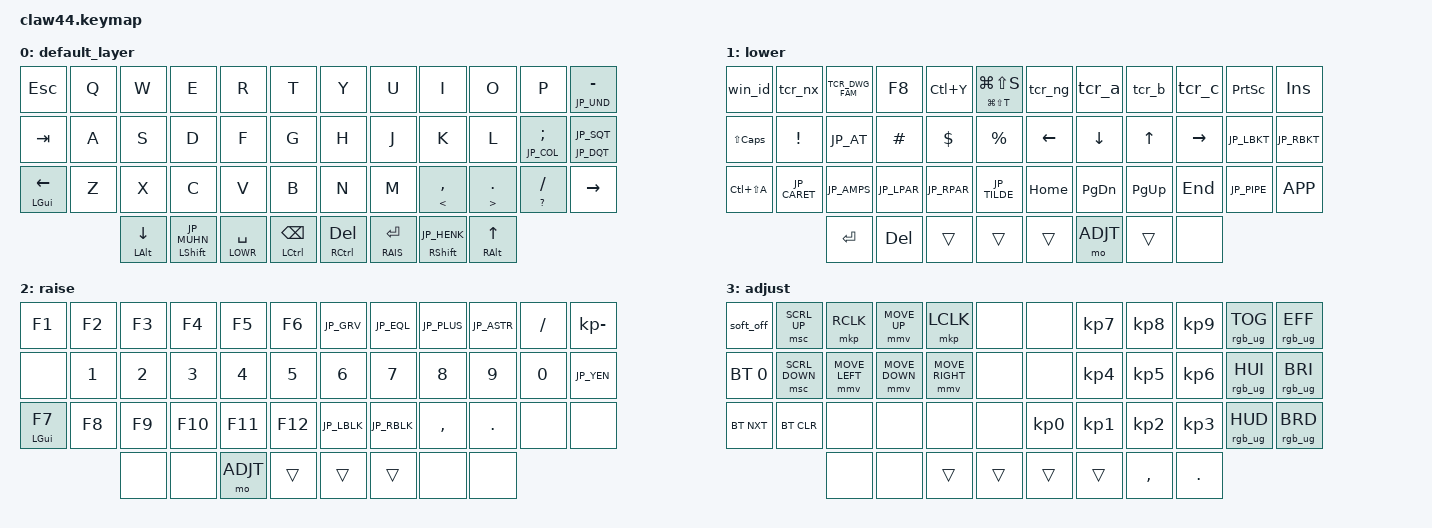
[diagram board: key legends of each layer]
/*
 * Copyright (c) 2021 The ZMK Contributors
 *
 * SPDX-License-Identifier: MIT
 */

#include <behaviors.dtsi>
#include <dt-bindings/zmk/keys.h>
#include <dt-bindings/zmk/bt.h>
#include <dt-bindings/zmk/outputs.h>
#include <dt-bindings/zmk/pointing.h>
#include <dt-bindings/zmk/rgb.h>

#define LOWR 1
#define RAIS 2
#define ADJT 3

/* the following lines are for using Claw44 on JIS layout */
#define JP_UND   LS(INT1)  // _
#define JP_COL   SQT       // :
#define JP_SQT   LS(N7)    // '
#define JP_DQT   LS(N2)    // "
#define JP_MUHN  INT5      // mukenkan
#define JP_HENK  INT4      // hankan
#define JP_AT    LBKT      // @
#define JP_CARET EQUAL     // ^
#define JP_AMPS  LS(N6)    // &
#define JP_LPAR  LS(N8)    // (
#define JP_RPAR  LPAR      // )
#define JP_TILDE LS(EQUAL) // ~
#define JP_LBLK  RBKT      // [
#define JP_RBLK  NUHS      // ]
#define JP_PIPE  LS(INT3)  // |
#define JP_ASTR  LS(SQT)   // ASTER
#define JP_LBKT  LS(RBKT)  // {
#define JP_RBKT  LS(NUHS)  // }
#define JP_GRV   LS(LBKT)  // `
#define JP_EQL   LS(MINUS) // =
#define JP_PLUS  LS(SEMI)  // +
#define JP_YEN   INT1      // yen

/* the following lines are for shortening keymap section */
#define TCR_DWG_FAM &tcr_dwg_fam &kp &kp
#define OCL_PSCR    &mt LG(LS(T)) LG(LS(S))
#define A_DWN       &mt LALT DOWN
#define S_MUHN      &mt LSHFT JP_MUHN
#define L_SPC       &lt LOWR SPACE
#define C_BS        &mt LCTRL BSPC
#define C_DEL       &mt RCTRL DEL
#define R_ENT       &lt RAIS ENTER
#define S_HENK      &mt RSHFT JP_HENK
#define A_UP        &mt RALT UP

&lt {
    quick-tap-ms = <170>;
};
&mt {
    quick-tap-ms = <170>;
    flavor = "tap-preferred";
};

&led_strip {
    chain-length = <6>;
};

/ {
    macros {
        ZMK_MACRO(win_id,
            wait-ms = <20>;
            tap-ms = <40>;
            bindings
                = <&kp LC(LA(DEL))>
                , <&macro_wait_time 2000>
                , <&kp DEL>
                , <&macro_wait_time 20>
                , <&kp ENTER>
                ;
        )

        ZMK_MACRO(tcr_fam,
            wait-ms = <30>;
            tap-ms = <40>;
            bindings
                = <&kp LS(TAB) &kp LS(TAB)>
                , <&macro_wait_time 3000>
                , <&kp HOME>
                ;
        )

       ZMK_MACRO(tcr_dwg,
            wait-ms = <30>;
            tap-ms = <40>;
            bindings
                = <&kp LS(TAB) &kp LS(TAB)>
                , <&macro_wait_time 3000>
                , <&kp END>
                ;
        )

        ZMK_MACRO(tcr_nx,
            wait-ms = <30>;
            tap-ms = <40>;
            bindings
                = <&kp LS(TAB) &kp LS(TAB) &kp LS(TAB) &kp LS(TAB) &kp LS(TAB) &kp LS(TAB)>
                , <&macro_wait_time 1000>
                , <&kp ENTER>
                , <&macro_wait_time 30>
                , <&mmv MOVE_X(30000) &mmv MOVE_X(30000) &mmv MOVE_X(30000) &mmv MOVE_X(30000) &mmv MOVE_X(30000) &mmv MOVE_X(30000) &mmv MOVE_X(30000)>
                , <&macro_wait_time 400>
                , <&mmv MOVE_Y(30000)>
                , <&macro_wait_time 30>
                , <&mkp LCLK>
                , <&kp LS(TAB) &kp LS(TAB)>
                , <&macro_wait_time 3000>
                , <&kp END>
                , <&macro_wait_time 30>
                , <&kp TAB &kp HOME>
                , <&mmv MOVE_X(-30000) &mmv MOVE_X(-30000) &mmv MOVE_X(-30000) &mmv MOVE_X(-30000) &mmv MOVE_X(-30000) &mmv MOVE_X(-30000) &mmv MOVE_X(-30000)>
                ;
        )

        ZMK_MACRO(tcr_ng,
            wait-ms = <30>;
            tap-ms = <40>;
            bindings
                = <&macro_wait_time 300>
                , <&kp LS(TAB)>
                , <&macro_wait_time 30>
                , <&kp SPACE>
                , <&kp LS(TAB) &kp LS(TAB) &kp LS(TAB) &kp LS(TAB) &kp LS(TAB) &kp LS(TAB)>
                , <&macro_wait_time 1000>
                , <&kp ENTER>
                , <&macro_wait_time 30>
                , <&mmv MOVE_X(30000) &mmv MOVE_X(30000) &mmv MOVE_X(30000) &mmv MOVE_X(30000) &mmv MOVE_X(30000) &mmv MOVE_X(30000) &mmv MOVE_X(30000)>
                , <&macro_wait_time 400>
                , <&mmv MOVE_Y(30000)>
                , <&macro_wait_time 30>
                , <&mkp LCLK>
                , <&kp LS(TAB) &kp LS(TAB)>
                , <&macro_wait_time 3000>
                , <&kp END>
                , <&macro_wait_time 30>
                , <&kp TAB &kp HOME>
                , <&mmv MOVE_X(-30000) &mmv MOVE_X(-30000) &mmv MOVE_X(-30000) &mmv MOVE_X(-30000) &mmv MOVE_X(-30000) &mmv MOVE_X(-30000) &mmv MOVE_X(-30000)>
                ;
        )

        ZMK_MACRO(tcr_a,
            wait-ms = <30>;
            tap-ms = <40>;
            bindings
                = <&kp LS(TAB) &kp LS(TAB) &kp DOWN>
                , <&kp LS(TAB) &kp LS(TAB) &kp LS(TAB) &kp LS(TAB) &kp LS(TAB) &kp LS(TAB)>
                , <&macro_wait_time 1000>
                , <&kp ENTER>
                , <&macro_wait_time 30>
                , <&mmv MOVE_X(30000) &mmv MOVE_X(30000) &mmv MOVE_X(30000) &mmv MOVE_X(30000) &mmv MOVE_X(30000) &mmv MOVE_X(30000) &mmv MOVE_X(30000)>
                , <&macro_wait_time 400>
                , <&mmv MOVE_Y(30000)>
                , <&macro_wait_time 30>
                , <&mkp LCLK>
                , <&kp LS(TAB) &kp LS(TAB)>
                , <&macro_wait_time 3000>
                , <&kp END>
                , <&macro_wait_time 30>
                , <&kp TAB &kp HOME>
                , <&mmv MOVE_X(-30000) &mmv MOVE_X(-30000) &mmv MOVE_X(-30000) &mmv MOVE_X(-30000) &mmv MOVE_X(-30000) &mmv MOVE_X(-30000) &mmv MOVE_X(-30000)>
                ;
        )

        ZMK_MACRO(tcr_b,
            wait-ms = <30>;
            tap-ms = <40>;
            bindings
                = <&kp LS(TAB) &kp LS(TAB) &kp DOWN &kp DOWN>
                , <&kp LS(TAB) &kp LS(TAB) &kp LS(TAB) &kp LS(TAB) &kp LS(TAB) &kp LS(TAB)>
                , <&macro_wait_time 1000>
                , <&kp ENTER>
                , <&macro_wait_time 30>
                , <&mmv MOVE_X(30000) &mmv MOVE_X(30000) &mmv MOVE_X(30000) &mmv MOVE_X(30000) &mmv MOVE_X(30000) &mmv MOVE_X(30000) &mmv MOVE_X(30000)>
                , <&macro_wait_time 400>
                , <&mmv MOVE_Y(30000)>
                , <&macro_wait_time 30>
                , <&mkp LCLK>
                , <&kp LS(TAB) &kp LS(TAB)>
                , <&macro_wait_time 3000>
                , <&kp END>
                , <&macro_wait_time 30>
                , <&kp TAB &kp HOME>
                , <&mmv MOVE_X(-30000) &mmv MOVE_X(-30000) &mmv MOVE_X(-30000) &mmv MOVE_X(-30000) &mmv MOVE_X(-30000) &mmv MOVE_X(-30000) &mmv MOVE_X(-30000)>
                ;
        )

        ZMK_MACRO(tcr_c,
            wait-ms = <30>;
            tap-ms = <40>;
            bindings
                = <&kp LS(TAB) &kp LS(TAB) &kp DOWN &kp DOWN &kp DOWN>
                , <&kp LS(TAB) &kp LS(TAB) &kp LS(TAB) &kp LS(TAB) &kp LS(TAB) &kp LS(TAB)>
                , <&macro_wait_time 1000>
                , <&kp ENTER>
                , <&macro_wait_time 30>
                , <&mmv MOVE_X(30000) &mmv MOVE_X(30000) &mmv MOVE_X(30000) &mmv MOVE_X(30000) &mmv MOVE_X(30000) &mmv MOVE_X(30000) &mmv MOVE_X(30000)>
                , <&macro_wait_time 400>
                , <&mmv MOVE_Y(30000)>
                , <&macro_wait_time 30>
                , <&mkp LCLK>
                , <&kp LS(TAB) &kp LS(TAB)>
                , <&macro_wait_time 3000>
                , <&kp END>
                , <&macro_wait_time 30>
                , <&kp TAB &kp HOME>
                , <&mmv MOVE_X(-30000) &mmv MOVE_X(-30000) &mmv MOVE_X(-30000) &mmv MOVE_X(-30000) &mmv MOVE_X(-30000) &mmv MOVE_X(-30000) &mmv MOVE_X(-30000)>
                ;
        )
    };

    behaviors {
        tcr_dwg_fam: tcr_dwg_fam {
            compatible = "zmk,behavior-hold-tap";
            bindings = <&tcr_fam>, <&tcr_dwg>;
            #binding-cells = <2>;
            tapping-term-ms = <300>;
        };
    };

    keymap {
        compatible = "zmk,keymap";

        default_layer {
   /* -------------------------------------------------------------   -------------------------------------------------------------
      |   ESC   |    Q    |    W    |    E    |    R    |    T    |   |    Y    |    U    |    I    |    O    |    P    |   -  _  |
      |   TAB   |    A    |    S    |    D    |    F    |    G    |   |    H    |    J    |    K    |    L    |   ;  :  |   '  "  |
      |LEFT  GUI|    Z    |    X    |    C    |    V    |    B    |   |    N    |    M    |   ,  <  |   .  >  |   /  ?  |  RIGHT  |
      --------------------|DOWN ALT |MUHEN SFT|SPC lower|BSPC CTL |   | DEL CTL |ENT raise|HENK SFT |  UP SFT |--------------------
                          -----------------------------------------   -----------------------------------------
   */
            bindings = <
    &kp ESC        &kp Q  &kp W  &kp E   &kp R  &kp T      &kp Y  &kp U  &kp I         &kp O       &kp P            &mt JP_UND MINUS
    &kp TAB        &kp A  &kp S  &kp D   &kp F  &kp G      &kp H  &kp J  &kp K         &kp L       &mt JP_COL SEMI  &mt JP_DQT JP_SQT
    &mt LGUI LEFT  &kp Z  &kp X  &kp C   &kp V  &kp B      &kp N  &kp M  &mt LT COMMA  &mt GT DOT  &mt QMARK FSLH   &kp RIGHT
                          A_DWN  S_MUHN  L_SPC  C_BS       C_DEL  R_ENT  S_HENK        A_UP
            >;
        };

        lower {
/*  -------------------------------------------------------------   -------------------------------------------------------------
    | win_id  | tcr_nx  | DWG_FAM |    F8   |  Ctrl+Y |PSCR OCL |   | tcr_ng  |  tcr_a  |  tcr_b  |  tcr_c  |  PSCRN  |   INS   |
    |  CAPS   |    !    |    @    |    #    |    $    |    %    |   |   LEFT  |   DOWN  |    UP   |  RIGHT  |    {    |    }    |
    |  CLCL   |    ^    |    &    |    (    |    )    |    ~    |   |   HOME  |  PG_DN  |  PG_UP  |   END   |    |    |   APP   |
    --------------------|  ENTER  |   DEL   |  xxxxx  |BSPC CTL |   | DEL CTL |  adjust |HENK SFT |  UP SFT |--------------------
                        -----------------------------------------   -----------------------------------------
*/
            bindings = <
    &win_id        &tcr_nx       TCR_DWG_FAM  &kp F8       &kp LC(Y)    OCL_PSCR          &tcr_ng    &tcr_a     &tcr_b     &tcr_c     &kp PSCRN    &kp INS
    &kp LS(CAPS)   &kp EXCL      &kp JP_AT    &kp HASH     &kp DLLR     &kp PRCNT         &kp LEFT   &kp DOWN   &kp UP     &kp RIGHT  &kp JP_LBKT  &kp JP_RBKT
    &kp LC(LS(A))  &kp JP_CARET  &kp JP_AMPS  &kp JP_LPAR  &kp JP_RPAR  &kp JP_TILDE      &kp HOME   &kp PG_DN  &kp PG_UP  &kp END    &kp JP_PIPE  &kp K_APP
                                 &kp ENTER    &kp DEL      &trans       &trans            &trans     &mo ADJT   &trans     &none
            >;
        };

        raise {
/*  -------------------------------------------------------------   -------------------------------------------------------------
    |    F1   |    F2   |    F3   |    F4   |    F5   |    F6   |   |    `    |    =    |    +    |  ASTER  |    /    |    -    |
    |         |    1    |    2    |    3    |    4    |    5    |   |    6    |    7    |    8    |    9    |    0    |    \    |
    |  F7 GUI |    F8   |    F9   |   F10   |   F11   |   F12   |   |    [    |    ]    |    ,    |    .    |         |         |
    --------------------|         |         |  adjust |BSPC CTL |   | DEL CTL |  xxxxx  |         |         |--------------------
                        -----------------------------------------   -----------------------------------------
*/
            bindings = <
    &kp F1       &kp F2  &kp F3  &kp F4   &kp F5    &kp F6       &kp JP_GRV   &kp JP_EQL   &kp JP_PLUS  &kp JP_ASTR  &kp FSLH  &kp KP_MINUS
    &none        &kp N1  &kp N2  &kp N3   &kp N4    &kp N5       &kp N6       &kp N7       &kp N8       &kp N9       &kp N0    &kp JP_YEN
    &mt LGUI F7  &kp F8  &kp F9  &kp F10  &kp F11   &kp F12      &kp JP_LBLK  &kp JP_RBLK  &kp COMMA    &kp DOT      &none     &none   
                         &none   &none    &mo ADJT  &trans       &trans       &trans       &none        &none
            >;
        };

        adjust {
/*  -------------------------------------------------------------   -------------------------------------------------------------
    | SOFT_OFF| SCRL_UP |  RCLK   |   UP    |  LCLK   |         |   |         |    7    |    8    |    9    | RGB_TOG | RGB_EFF |
    | BT_SEL0 | SCRL_DW |  LEFT   |  DOWN   |  RIGHT  |         |   |         |    4    |    5    |    6    | RGB_HUI | RGB_BRI |
    | BT_NXT  | BT_CLR  |         |         |         |         |   |    0    |    1    |    2    |    3    | RGB_HUD | RGB_BRD |
    --------------------|         |         |  xxxxx  |BSPC CTL |   | DEL CTL |  xxxxx  |    ,    |    .    |--------------------
                        -----------------------------------------   -----------------------------------------
*/
            bindings = <
    &soft_off    &msc SCRL_UP    &mkp RCLK       &mmv MOVE_UP    &mkp LCLK        &none       &none      &kp KP_N7  &kp KP_N8  &kp KP_N9  &rgb_ug RGB_TOG  &rgb_ug RGB_EFF
    &bt BT_SEL 0 &msc SCRL_DOWN  &mmv MOVE_LEFT  &mmv MOVE_DOWN  &mmv MOVE_RIGHT  &none       &none      &kp KP_N4  &kp KP_N5  &kp KP_N6  &rgb_ug RGB_HUI  &rgb_ug RGB_BRI
    &bt BT_NXT   &bt BT_CLR      &none           &none           &none            &none       &kp KP_N0  &kp KP_N1  &kp KP_N2  &kp KP_N3  &rgb_ug RGB_HUD  &rgb_ug RGB_BRD
                                 &none           &none           &trans           &trans      &trans     &trans     &kp COMMA  &kp DOT
            >;
        };
    };
};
